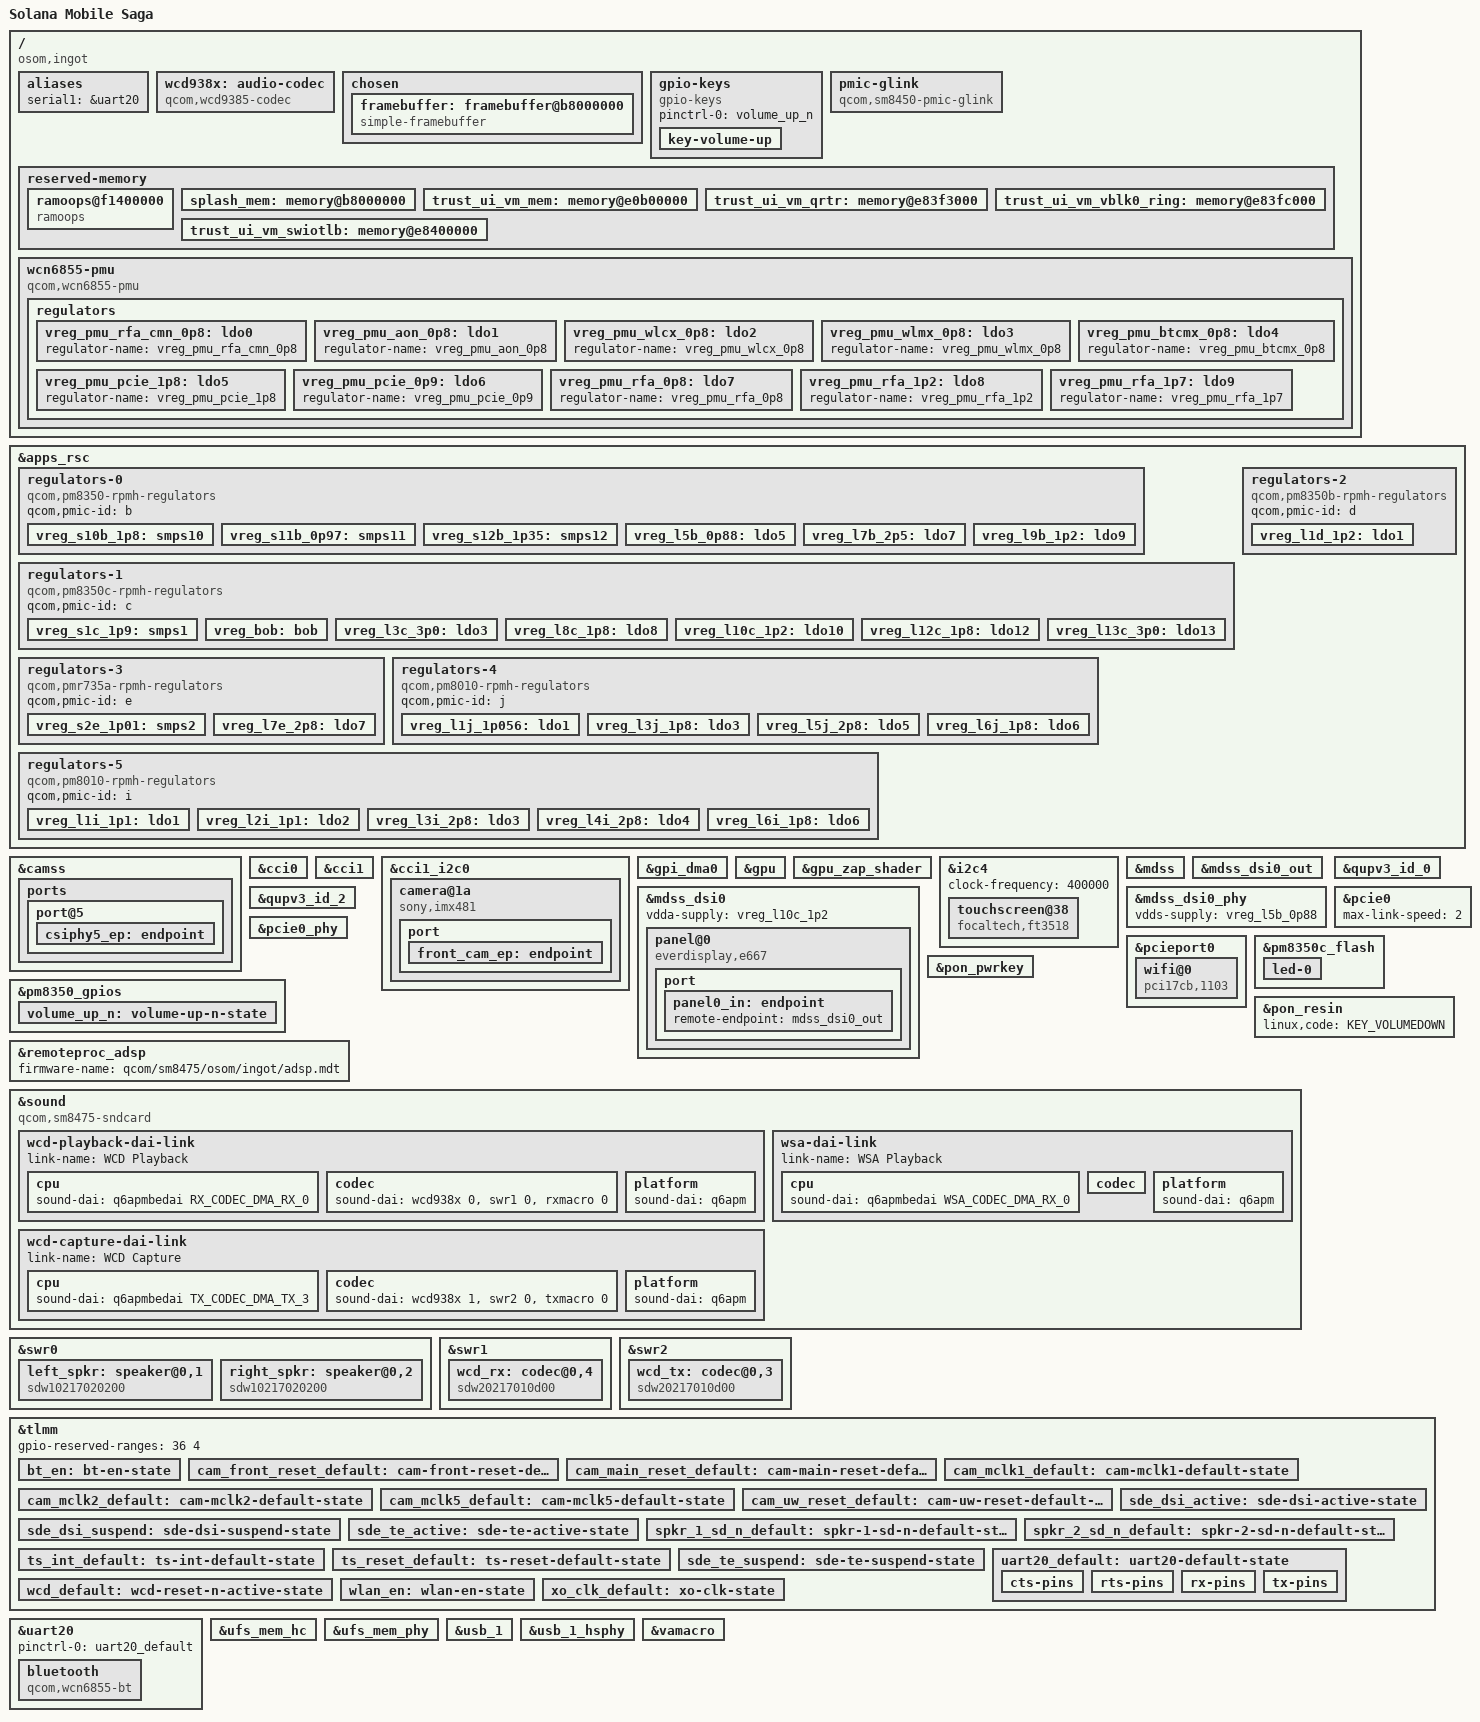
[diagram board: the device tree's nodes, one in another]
// SPDX-License-Identifier: BSD-3-Clause
/*
 * Solana Mobile Saga (OSOM ingot)
 *
 * Bring-up description: the display, touch, the buttons, UFS and USB 2.0 in
 * peripheral mode. The GPU, the remote processors and the radios stay off
 * until each is brought up on its own.
 *
 * Audio: a WCD938x codec for the analog microphones on the RX and TX
 * SoundWire buses, and two WSA883x speaker amplifiers on the WSA bus. The
 * second WSA bus and its macro are unused.
 */

/dts-v1/;

#include <dt-bindings/input/input.h>
#include <dt-bindings/leds/common.h>
#include <dt-bindings/pinctrl/qcom,pmic-gpio.h>
#include <dt-bindings/regulator/qcom,rpmh-regulator.h>
#include <dt-bindings/sound/qcom,q6dsp-lpass-ports.h>

#include "sm8475.dtsi"
#include "pm8350.dtsi"
#include "pm8350b.dtsi"
#include "pm8350c.dtsi"
#include "pm8450.dtsi"
#include "pmk8350.dtsi"
#include "pmr735a.dtsi"

/*
 * The trusted UI VM is larger here than on SM8450, so its shared
 * regions move up.
 */
/delete-node/ &trust_ui_vm_mem;
/delete-node/ &trust_ui_vm_qrtr;
/delete-node/ &trust_ui_vm_vblk0_ring;
/delete-node/ &trust_ui_vm_swiotlb;

/ {
	model = "Solana Mobile Saga";
	compatible = "osom,ingot", "qcom,sm8475";
	chassis-type = "handset";

	aliases {
		serial1 = &uart20;
	};

	wcd938x: audio-codec {
		compatible = "qcom,wcd9385-codec";

		pinctrl-0 = <&wcd_default>;
		pinctrl-names = "default";

		qcom,micbias1-microvolt = <1800000>;
		qcom,micbias2-microvolt = <1800000>;
		qcom,micbias3-microvolt = <1800000>;
		qcom,micbias4-microvolt = <1800000>;
		qcom,mbhc-buttons-vthreshold-microvolt = <75000 150000 237000 500000 500000 500000 500000 500000>;
		qcom,mbhc-headset-vthreshold-microvolt = <1700000>;
		qcom,mbhc-headphone-vthreshold-microvolt = <50000>;
		qcom,rx-device = <&wcd_rx>;
		qcom,tx-device = <&wcd_tx>;

		reset-gpios = <&tlmm 43 GPIO_ACTIVE_LOW>;

		vdd-buck-supply = <&vreg_s10b_1p8>;
		vdd-rxtx-supply = <&vreg_s10b_1p8>;
		vdd-io-supply = <&vreg_s10b_1p8>;
		vdd-mic-bias-supply = <&vreg_bob>;

		#sound-dai-cells = <1>;
	};

	chosen {
		#address-cells = <2>;
		#size-cells = <2>;
		ranges;

		framebuffer: framebuffer@b8000000 {
			compatible = "simple-framebuffer";
			reg = <0x0 0xb8000000 0x0 0x2b00000>;
			width = <1080>;
			height = <2400>;
			stride = <(1080 * 4)>;
			format = "a8r8g8b8";

			clocks = <&gcc GCC_DISP_HF_AXI_CLK>;
		};
	};

	gpio-keys {
		compatible = "gpio-keys";

		pinctrl-0 = <&volume_up_n>;
		pinctrl-names = "default";

		key-volume-up {
			label = "Volume Up";
			linux,code = <KEY_VOLUMEUP>;
			gpios = <&pm8350_gpios 6 GPIO_ACTIVE_LOW>;
			debounce-interval = <15>;
			linux,can-disable;
			wakeup-source;
		};
	};

	/*
	 * The ADSP firmware owns the charger and the fuel gauge. The USB-C
	 * connector is left out for now so nothing here takes part in USB
	 * role switching.
	 */
	pmic-glink {
		compatible = "qcom,sm8450-pmic-glink", "qcom,pmic-glink";
	};

	reserved-memory {
		/* Stock's layout, so either system reads the other's last console */
		ramoops@f1400000 {
			compatible = "ramoops";
			reg = <0x0 0xf1400000 0x0 0x400000>;
			console-size = <0x200000>;
			pmsg-size = <0x200000>;
			no-map;
		};

		splash_mem: memory@b8000000 {
			reg = <0x0 0xb8000000 0x0 0x2b00000>;
			no-map;
		};

		trust_ui_vm_mem: memory@e0b00000 {
			reg = <0x0 0xe0b00000 0x0 0x78f3000>;
			no-map;
		};

		trust_ui_vm_qrtr: memory@e83f3000 {
			reg = <0x0 0xe83f3000 0x0 0x9000>;
			no-map;
		};

		trust_ui_vm_vblk0_ring: memory@e83fc000 {
			reg = <0x0 0xe83fc000 0x0 0x4000>;
			no-map;
		};

		trust_ui_vm_swiotlb: memory@e8400000 {
			reg = <0x0 0xe8400000 0x0 0x100000>;
			no-map;
		};
	};

	wcn6855-pmu {
		compatible = "qcom,wcn6855-pmu";

		pinctrl-0 = <&bt_en>, <&wlan_en>, <&xo_clk_default>;
		pinctrl-names = "default";

		wlan-enable-gpios = <&tlmm 80 GPIO_ACTIVE_HIGH>;
		bt-enable-gpios = <&tlmm 81 GPIO_ACTIVE_HIGH>;
		swctrl-gpios = <&tlmm 82 GPIO_ACTIVE_HIGH>;
		xo-clk-gpios = <&tlmm 204 GPIO_ACTIVE_HIGH>;

		vddio-supply = <&vreg_s10b_1p8>;
		vddaon-supply = <&vreg_s11b_0p97>;
		vddpmu-supply = <&vreg_s12b_1p35>;
		vddpmumx-supply = <&vreg_s2e_1p01>;
		vddpmucx-supply = <&vreg_s11b_0p97>;
		vddrfa0p95-supply = <&vreg_s11b_0p97>;
		vddrfa1p3-supply = <&vreg_s12b_1p35>;
		vddrfa1p9-supply = <&vreg_s1c_1p9>;
		vddpcie1p3-supply = <&vreg_s12b_1p35>;
		vddpcie1p9-supply = <&vreg_s1c_1p9>;

		regulators {
			vreg_pmu_rfa_cmn_0p8: ldo0 {
				regulator-name = "vreg_pmu_rfa_cmn_0p8";
			};

			vreg_pmu_aon_0p8: ldo1 {
				regulator-name = "vreg_pmu_aon_0p8";
			};

			vreg_pmu_wlcx_0p8: ldo2 {
				regulator-name = "vreg_pmu_wlcx_0p8";
			};

			vreg_pmu_wlmx_0p8: ldo3 {
				regulator-name = "vreg_pmu_wlmx_0p8";
			};

			vreg_pmu_btcmx_0p8: ldo4 {
				regulator-name = "vreg_pmu_btcmx_0p8";
			};

			vreg_pmu_pcie_1p8: ldo5 {
				regulator-name = "vreg_pmu_pcie_1p8";
			};

			vreg_pmu_pcie_0p9: ldo6 {
				regulator-name = "vreg_pmu_pcie_0p9";
			};

			vreg_pmu_rfa_0p8: ldo7 {
				regulator-name = "vreg_pmu_rfa_0p8";
			};

			vreg_pmu_rfa_1p2: ldo8 {
				regulator-name = "vreg_pmu_rfa_1p2";
			};

			vreg_pmu_rfa_1p7: ldo9 {
				regulator-name = "vreg_pmu_rfa_1p7";
			};
		};
	};
};

&apps_rsc {
	regulators-0 {
		compatible = "qcom,pm8350-rpmh-regulators";
		qcom,pmic-id = "b";

		/*
		 * Besides the WCN6855, S10B feeds 1.8 V loads such as the eUSB2
		 * repeater, and S11B and S12B are the parents of LDOs in use (in
		 * the reference power tree S12B feeds L9B for UFS and L10C for
		 * the USB and DSI PHYs). The bootloader leaves them on and the
		 * LDO parents are not described, so keep them on once Linux
		 * takes a vote: the WCN6855 powering down must not take the
		 * rest with it.
		 */
		vreg_s10b_1p8: smps10 {
			regulator-name = "vreg_s10b_1p8";
			regulator-min-microvolt = <1800000>;
			regulator-max-microvolt = <1800000>;
			regulator-always-on;
		};

		vreg_s11b_0p97: smps11 {
			regulator-name = "vreg_s11b_0p97";
			regulator-min-microvolt = <968000>;
			regulator-max-microvolt = <968000>;
			regulator-always-on;
		};

		vreg_s12b_1p35: smps12 {
			regulator-name = "vreg_s12b_1p35";
			regulator-min-microvolt = <1352000>;
			regulator-max-microvolt = <1352000>;
			regulator-always-on;
		};

		vreg_l5b_0p88: ldo5 {
			regulator-name = "vreg_l5b_0p88";
			regulator-min-microvolt = <720000>;
			regulator-max-microvolt = <958000>;
			regulator-initial-mode = <RPMH_REGULATOR_MODE_HPM>;
		};

		vreg_l7b_2p5: ldo7 {
			regulator-name = "vreg_l7b_2p5";
			regulator-min-microvolt = <2400000>;
			regulator-max-microvolt = <3544000>;
			regulator-initial-mode = <RPMH_REGULATOR_MODE_HPM>;
		};

		vreg_l9b_1p2: ldo9 {
			regulator-name = "vreg_l9b_1p2";
			regulator-min-microvolt = <1200000>;
			regulator-max-microvolt = <1304000>;
			regulator-initial-mode = <RPMH_REGULATOR_MODE_HPM>;
		};
	};

	regulators-1 {
		compatible = "qcom,pm8350c-rpmh-regulators";
		qcom,pmic-id = "c";

		/* Also the parent of PMR735A L4-L6, kept on for the same reason */
		vreg_s1c_1p9: smps1 {
			regulator-name = "vreg_s1c_1p9";
			regulator-min-microvolt = <1904000>;
			regulator-max-microvolt = <1904000>;
			regulator-always-on;
		};

		vreg_bob: bob {
			regulator-name = "vreg_bob";
			regulator-min-microvolt = <3008000>;
			regulator-max-microvolt = <3960000>;
			regulator-initial-mode = <RPMH_REGULATOR_MODE_AUTO>;
		};

		vreg_l3c_3p0: ldo3 {
			regulator-name = "vreg_l3c_3p0";
			regulator-min-microvolt = <3000000>;
			regulator-max-microvolt = <3300000>;
			regulator-initial-mode = <RPMH_REGULATOR_MODE_HPM>;
		};

		vreg_l8c_1p8: ldo8 {
			regulator-name = "vreg_l8c_1p8";
			regulator-min-microvolt = <1800000>;
			regulator-max-microvolt = <2000000>;
			regulator-initial-mode = <RPMH_REGULATOR_MODE_HPM>;
		};

		vreg_l10c_1p2: ldo10 {
			regulator-name = "vreg_l10c_1p2";
			regulator-min-microvolt = <1200000>;
			regulator-max-microvolt = <1304000>;
			regulator-initial-mode = <RPMH_REGULATOR_MODE_HPM>;
		};

		vreg_l12c_1p8: ldo12 {
			regulator-name = "vreg_l12c_1p8";
			regulator-min-microvolt = <1800000>;
			regulator-max-microvolt = <1800000>;
			regulator-initial-mode = <RPMH_REGULATOR_MODE_HPM>;
		};

		vreg_l13c_3p0: ldo13 {
			regulator-name = "vreg_l13c_3p0";
			regulator-min-microvolt = <3000000>;
			regulator-max-microvolt = <3300000>;
			regulator-initial-mode = <RPMH_REGULATOR_MODE_HPM>;
		};
	};

	regulators-2 {
		compatible = "qcom,pm8350b-rpmh-regulators";
		qcom,pmic-id = "d";

		vreg_l1d_1p2: ldo1 {
			regulator-name = "vreg_l1d_1p2";
			regulator-min-microvolt = <1200000>;
			regulator-max-microvolt = <1296000>;
			regulator-initial-mode = <RPMH_REGULATOR_MODE_HPM>;
		};
	};

	regulators-3 {
		compatible = "qcom,pmr735a-rpmh-regulators";
		qcom,pmic-id = "e";

		vreg_s2e_1p01: smps2 {
			regulator-name = "vreg_s2e_1p01";
			regulator-min-microvolt = <1012000>;
			regulator-max-microvolt = <1012000>;
		};

		/*
		 * Supply of the Wi-Fi/Bluetooth antenna switch, which the
		 * WCN6855 PMU binding has no input for
		 */
		vreg_l7e_2p8: ldo7 {
			regulator-name = "vreg_l7e_2p8";
			regulator-min-microvolt = <2800000>;
			regulator-max-microvolt = <2800000>;
			regulator-initial-mode = <RPMH_REGULATOR_MODE_HPM>;
			regulator-always-on;
		};
	};

	/*
	 * The second of the two PM8010 camera PMICs. Only the camera sensor
	 * rails are described for now.
	 */
	regulators-4 {
		compatible = "qcom,pm8010-rpmh-regulators";
		qcom,pmic-id = "j";

		vreg_l1j_1p056: ldo1 {
			regulator-name = "vreg_l1j_1p056";
			regulator-min-microvolt = <1056000>;
			regulator-max-microvolt = <1056000>;
			regulator-initial-mode = <RPMH_REGULATOR_MODE_HPM>;
		};

		vreg_l3j_1p8: ldo3 {
			regulator-name = "vreg_l3j_1p8";
			regulator-min-microvolt = <1800000>;
			regulator-max-microvolt = <1800000>;
			regulator-initial-mode = <RPMH_REGULATOR_MODE_HPM>;
		};

		vreg_l5j_2p8: ldo5 {
			regulator-name = "vreg_l5j_2p8";
			regulator-min-microvolt = <2800000>;
			regulator-max-microvolt = <2800000>;
			regulator-initial-mode = <RPMH_REGULATOR_MODE_HPM>;
		};

		vreg_l6j_1p8: ldo6 {
			regulator-name = "vreg_l6j_1p8";
			regulator-min-microvolt = <1800000>;
			regulator-max-microvolt = <1800000>;
			regulator-initial-mode = <RPMH_REGULATOR_MODE_HPM>;
		};
	};

	/*
	 * The first of the two PM8010 camera PMICs. Only the rear camera
	 * sensor rails are described for now.
	 */
	regulators-5 {
		compatible = "qcom,pm8010-rpmh-regulators";
		qcom,pmic-id = "i";

		vreg_l1i_1p1: ldo1 {
			regulator-name = "vreg_l1i_1p1";
			regulator-min-microvolt = <1104000>;
			regulator-max-microvolt = <1104000>;
			regulator-initial-mode = <RPMH_REGULATOR_MODE_HPM>;
		};

		vreg_l2i_1p1: ldo2 {
			regulator-name = "vreg_l2i_1p1";
			regulator-min-microvolt = <1104000>;
			regulator-max-microvolt = <1104000>;
			regulator-initial-mode = <RPMH_REGULATOR_MODE_HPM>;
		};

		vreg_l3i_2p8: ldo3 {
			regulator-name = "vreg_l3i_2p8";
			regulator-min-microvolt = <2800000>;
			regulator-max-microvolt = <2800000>;
			regulator-initial-mode = <RPMH_REGULATOR_MODE_HPM>;
		};

		vreg_l4i_2p8: ldo4 {
			regulator-name = "vreg_l4i_2p8";
			regulator-min-microvolt = <2800000>;
			regulator-max-microvolt = <2800000>;
			regulator-initial-mode = <RPMH_REGULATOR_MODE_HPM>;
		};

		vreg_l6i_1p8: ldo6 {
			regulator-name = "vreg_l6i_1p8";
			regulator-min-microvolt = <1800000>;
			regulator-max-microvolt = <1800000>;
			regulator-initial-mode = <RPMH_REGULATOR_MODE_HPM>;
		};
	};
};

&camss {
	vdda-phy-supply = <&vreg_l5b_0p88>;
	vdda-pll-supply = <&vreg_l10c_1p2>;

	status = "okay";

	ports {
		port@5 {
			csiphy5_ep: endpoint {
				clock-lanes = <7>;
				data-lanes = <0 1 2 3>;
				remote-endpoint = <&front_cam_ep>;
			};
		};
	};
};

&cci0 {
	status = "okay";
};

&cci1 {
	status = "okay";
};

&cci1_i2c0 {
	camera@1a {
		compatible = "sony,imx481";
		reg = <0x1a>;

		clocks = <&camcc CAM_CC_MCLK5_CLK>;
		assigned-clocks = <&camcc CAM_CC_MCLK5_CLK>;
		assigned-clock-rates = <24000000>;

		power-domains = <&camcc TITAN_TOP_GDSC>;

		reset-gpios = <&tlmm 118 GPIO_ACTIVE_LOW>;

		pinctrl-0 = <&cam_mclk5_default>, <&cam_front_reset_default>;
		pinctrl-names = "default";

		dovdd-supply = <&vreg_l3j_1p8>;
		avdd-supply = <&vreg_l5j_2p8>;
		dvdd-supply = <&vreg_l1j_1p056>;

		orientation = <0>;
		/*
		 * Mounted at 90 degrees: the picture needs a quarter turn
		 * clockwise to be upright in portrait, which is 270 degrees
		 * counter-clockwise, the direction this property counts in.
		 */
		rotation = <270>;

		port {
			front_cam_ep: endpoint {
				data-lanes = <1 2 3 4>;
				link-frequencies = /bits/ 64 <918000000>;
				remote-endpoint = <&csiphy5_ep>;
			};
		};
	};
};

&gpi_dma0 {
	status = "okay";
};

&gpu {
	status = "okay";
};

&gpu_zap_shader {
	firmware-name = "qcom/sm8475/osom/ingot/a730_zap.mbn";
};

&i2c4 {
	clock-frequency = <400000>;
	status = "okay";

	touchscreen@38 {
		compatible = "focaltech,ft3518";
		reg = <0x38>;

		interrupts-extended = <&tlmm 21 IRQ_TYPE_LEVEL_LOW>;
		reset-gpios = <&tlmm 20 GPIO_ACTIVE_LOW>;

		vcc-supply = <&vreg_l3c_3p0>;
		iovcc-supply = <&vreg_l8c_1p8>;

		pinctrl-0 = <&ts_int_default>, <&ts_reset_default>;
		pinctrl-names = "default";

		touchscreen-size-x = <1080>;
		touchscreen-size-y = <2400>;
	};
};

&mdss {
	status = "okay";
};

&mdss_dsi0 {
	vdda-supply = <&vreg_l10c_1p2>;
	status = "okay";

	panel@0 {
		compatible = "everdisplay,e667";
		reg = <0>;

		reset-gpios = <&tlmm 0 GPIO_ACTIVE_LOW>;

		vddio-supply = <&vreg_l12c_1p8>;
		vci-supply = <&vreg_l13c_3p0>;
		extvdd-supply = <&vreg_l1d_1p2>;

		pinctrl-0 = <&sde_dsi_active>, <&sde_te_active>;
		pinctrl-1 = <&sde_dsi_suspend>, <&sde_te_suspend>;
		pinctrl-names = "default", "sleep";

		port {
			panel0_in: endpoint {
				remote-endpoint = <&mdss_dsi0_out>;
			};
		};
	};
};

&mdss_dsi0_out {
	remote-endpoint = <&panel0_in>;
	data-lanes = <0 1 2 3>;
};

&mdss_dsi0_phy {
	vdds-supply = <&vreg_l5b_0p88>;
	status = "okay";
};

&qupv3_id_0 {
	status = "okay";
};

&qupv3_id_2 {
	status = "okay";
};

&pcie0 {
	/*
	 * DEBUG: deliver MSIs through the DWC controller's own MSI block
	 * (msi0..msi7) instead of the GIC ITS, to tell a broken ITS MSI path
	 * apart from a device that never finishes its DMA.
	 */
	/delete-property/ msi-map;
	/delete-property/ msi-map-mask;

	max-link-speed = <2>;

	status = "okay";
};

&pcie0_phy {
	vdda-phy-supply = <&vreg_l5b_0p88>;
	vdda-pll-supply = <&vreg_l10c_1p2>;

	status = "okay";
};

&pcieport0 {
	wifi@0 {
		compatible = "pci17cb,1103";
		reg = <0x10000 0x0 0x0 0x0 0x0>;

		vddrfacmn-supply = <&vreg_pmu_rfa_cmn_0p8>;
		vddaon-supply = <&vreg_pmu_aon_0p8>;
		vddwlcx-supply = <&vreg_pmu_wlcx_0p8>;
		vddwlmx-supply = <&vreg_pmu_wlmx_0p8>;
		vddpcie1p8-supply = <&vreg_pmu_pcie_1p8>;
		vddpcie0p9-supply = <&vreg_pmu_pcie_0p9>;
		vddrfa0p8-supply = <&vreg_pmu_rfa_0p8>;
		vddrfa1p2-supply = <&vreg_pmu_rfa_1p2>;
		vddrfa1p8-supply = <&vreg_pmu_rfa_1p7>;

		qcom,calibration-variant = "Solana_Saga";
	};
};

&pm8350_gpios {
	volume_up_n: volume-up-n-state {
		pins = "gpio6";
		function = "normal";
		power-source = <1>;
		input-enable;
		bias-pull-up;
	};
};

&pm8350c_flash {
	status = "okay";

	led-0 {
		function = LED_FUNCTION_FLASH;
		color = <LED_COLOR_ID_WHITE>;
		led-sources = <1>, <2>;
		led-max-microamp = <200000>;
		flash-max-microamp = <1500000>;
		flash-max-timeout-us = <1280000>;
	};
};

&pon_pwrkey {
	status = "okay";
};

&pon_resin {
	linux,code = <KEY_VOLUMEDOWN>;
	status = "okay";
};

&remoteproc_adsp {
	firmware-name = "qcom/sm8475/osom/ingot/adsp.mdt";
	status = "okay";
};

&sound {
	compatible = "qcom,sm8475-sndcard", "qcom,sm8450-sndcard";
	model = "SM8475-Solana-Saga";
	audio-routing = "SpkrLeft IN", "WSA_SPK1 OUT",
			"SpkrRight IN", "WSA_SPK2 OUT",
			"IN1_HPHL", "HPHL_OUT",
			"IN2_HPHR", "HPHR_OUT",
			"AMIC1", "MIC BIAS1",
			"AMIC2", "MIC BIAS2",
			"AMIC3", "MIC BIAS3",
			"AMIC4", "MIC BIAS3",
			"AMIC5", "MIC BIAS4",
			"TX SWR_INPUT0", "ADC1_OUTPUT",
			"TX SWR_INPUT1", "ADC2_OUTPUT",
			"TX SWR_INPUT0", "ADC3_OUTPUT",
			"TX SWR_INPUT1", "ADC4_OUTPUT";

	wcd-playback-dai-link {
		link-name = "WCD Playback";

		cpu {
			sound-dai = <&q6apmbedai RX_CODEC_DMA_RX_0>;
		};

		codec {
			sound-dai = <&wcd938x 0>, <&swr1 0>, <&rxmacro 0>;
		};

		platform {
			sound-dai = <&q6apm>;
		};
	};

	wcd-capture-dai-link {
		link-name = "WCD Capture";

		cpu {
			sound-dai = <&q6apmbedai TX_CODEC_DMA_TX_3>;
		};

		codec {
			sound-dai = <&wcd938x 1>, <&swr2 0>, <&txmacro 0>;
		};

		platform {
			sound-dai = <&q6apm>;
		};
	};

	wsa-dai-link {
		link-name = "WSA Playback";

		cpu {
			sound-dai = <&q6apmbedai WSA_CODEC_DMA_RX_0>;
		};

		codec {
			sound-dai = <&left_spkr>, <&right_spkr>, <&swr0 0>, <&wsamacro 0>;
		};

		platform {
			sound-dai = <&q6apm>;
		};
	};
};

&swr0 {
	status = "okay";

	left_spkr: speaker@0,1 {
		compatible = "sdw10217020200";
		reg = <0 1>;

		pinctrl-0 = <&spkr_1_sd_n_default>;
		pinctrl-names = "default";

		powerdown-gpios = <&tlmm 1 GPIO_ACTIVE_LOW>;
		vdd-supply = <&vreg_s10b_1p8>;

		#sound-dai-cells = <0>;
		sound-name-prefix = "SpkrLeft";
		#thermal-sensor-cells = <0>;
	};

	right_spkr: speaker@0,2 {
		compatible = "sdw10217020200";
		reg = <0 2>;

		pinctrl-0 = <&spkr_2_sd_n_default>;
		pinctrl-names = "default";

		powerdown-gpios = <&tlmm 89 GPIO_ACTIVE_LOW>;
		vdd-supply = <&vreg_s10b_1p8>;

		#sound-dai-cells = <0>;
		sound-name-prefix = "SpkrRight";
		#thermal-sensor-cells = <0>;
	};
};

&swr1 {
	status = "okay";

	wcd_rx: codec@0,4 {
		compatible = "sdw20217010d00";
		reg = <0 4>;
		qcom,rx-port-mapping = <1 2 3 4 5>;
	};
};

&swr2 {
	status = "okay";

	wcd_tx: codec@0,3 {
		compatible = "sdw20217010d00";
		reg = <0 3>;
		qcom,tx-port-mapping = <1 1 2 3>;
	};
};

&tlmm {
	gpio-reserved-ranges = <36 4>;

	bt_en: bt-en-state {
		pins = "gpio81";
		function = "gpio";
		drive-strength = <16>;
		output-low;
		bias-pull-down;
	};

	cam_front_reset_default: cam-front-reset-default-state {
		pins = "gpio118";
		function = "gpio";
		drive-strength = <2>;
		bias-disable;
	};

	cam_main_reset_default: cam-main-reset-default-state {
		pins = "gpio24";
		function = "gpio";
		drive-strength = <2>;
		bias-disable;
	};

	cam_mclk1_default: cam-mclk1-default-state {
		pins = "gpio101";
		function = "cam_mclk";
		drive-strength = <6>;
		bias-disable;
	};

	cam_mclk2_default: cam-mclk2-default-state {
		pins = "gpio102";
		function = "cam_mclk";
		drive-strength = <6>;
		bias-disable;
	};

	cam_mclk5_default: cam-mclk5-default-state {
		pins = "gpio105";
		function = "cam_mclk";
		drive-strength = <6>;
		bias-disable;
	};

	cam_uw_reset_default: cam-uw-reset-default-state {
		pins = "gpio117";
		function = "gpio";
		drive-strength = <2>;
		bias-disable;
	};

	sde_dsi_active: sde-dsi-active-state {
		pins = "gpio0";
		function = "gpio";
		drive-strength = <8>;
		bias-disable;
	};

	sde_dsi_suspend: sde-dsi-suspend-state {
		pins = "gpio0";
		function = "gpio";
		drive-strength = <2>;
		bias-pull-down;
	};

	sde_te_active: sde-te-active-state {
		pins = "gpio86";
		function = "mdp_vsync";
		drive-strength = <2>;
		bias-pull-down;
	};

	spkr_1_sd_n_default: spkr-1-sd-n-default-state {
		pins = "gpio1";
		function = "gpio";
		drive-strength = <16>;
		bias-disable;
		output-low;
	};

	spkr_2_sd_n_default: spkr-2-sd-n-default-state {
		pins = "gpio89";
		function = "gpio";
		drive-strength = <16>;
		bias-disable;
		output-low;
	};

	ts_int_default: ts-int-default-state {
		pins = "gpio21";
		function = "gpio";
		drive-strength = <2>;
		bias-pull-up;
	};

	ts_reset_default: ts-reset-default-state {
		pins = "gpio20";
		function = "gpio";
		drive-strength = <8>;
		bias-disable;
	};

	sde_te_suspend: sde-te-suspend-state {
		pins = "gpio86";
		function = "mdp_vsync";
		drive-strength = <2>;
		bias-pull-down;
	};

	uart20_default: uart20-default-state {
		cts-pins {
			pins = "gpio76";
			function = "qup20";
			bias-disable;
		};

		rts-pins {
			pins = "gpio77";
			function = "qup20";
			bias-disable;
		};

		rx-pins {
			pins = "gpio78";
			function = "qup20";
			bias-disable;
		};

		tx-pins {
			pins = "gpio79";
			function = "qup20";
			bias-disable;
		};
	};

	wcd_default: wcd-reset-n-active-state {
		pins = "gpio43";
		function = "gpio";
		drive-strength = <16>;
		bias-disable;
		output-low;
	};

	wlan_en: wlan-en-state {
		pins = "gpio80";
		function = "gpio";
		drive-strength = <16>;
		output-low;
		bias-pull-down;
	};

	xo_clk_default: xo-clk-state {
		pins = "gpio204";
		function = "gpio";
		drive-strength = <16>;
		output-low;
		bias-pull-down;
	};
};

&uart20 {
	pinctrl-0 = <&uart20_default>;
	pinctrl-names = "default";

	status = "okay";

	bluetooth {
		compatible = "qcom,wcn6855-bt";

		vddrfacmn-supply = <&vreg_pmu_rfa_cmn_0p8>;
		vddaon-supply = <&vreg_pmu_aon_0p8>;
		vddwlcx-supply = <&vreg_pmu_wlcx_0p8>;
		vddwlmx-supply = <&vreg_pmu_wlmx_0p8>;
		vddbtcmx-supply = <&vreg_pmu_btcmx_0p8>;
		vddrfa0p8-supply = <&vreg_pmu_rfa_0p8>;
		vddrfa1p2-supply = <&vreg_pmu_rfa_1p2>;
		vddrfa1p7-supply = <&vreg_pmu_rfa_1p7>;
	};
};

/*
 * USB 2.0 only, for the gadget link. The eUSB2 repeater keeps the
 * bootloader's setup for now.
 */
/*
 * UFS holds every partition, calibration included. The initramfs sets each
 * disk and partition read-only as it appears (device/ingot/initramfs/init).
 */
&ufs_mem_hc {
	reset-gpios = <&tlmm 210 GPIO_ACTIVE_LOW>;

	vcc-supply = <&vreg_l7b_2p5>;
	vcc-max-microamp = <1100000>;
	vccq-supply = <&vreg_l9b_1p2>;
	vccq-max-microamp = <1200000>;

	status = "okay";
};

&ufs_mem_phy {
	vdda-phy-supply = <&vreg_l5b_0p88>;
	vdda-pll-supply = <&vreg_l10c_1p2>;

	status = "okay";
};

&usb_1 {
	phys = <&usb_1_hsphy>;
	phy-names = "usb2-phy";
	maximum-speed = "high-speed";
	dr_mode = "peripheral";
	status = "okay";
};

&usb_1_hsphy {
	vdd-supply = <&vreg_l5b_0p88>;
	vdda12-supply = <&vreg_l10c_1p2>;
	status = "okay";
};

/* The VA macro provides the frame sync clock the other macros run from */
&vamacro {
	status = "okay";
};
